# USB0_MMR_MMRVBP_USBSS_CMN register map
Vendor: Texas Instruments
Peripheral module from a debugger description file (folder J7VCL).
Registers are 32-bit, access per field, reset 0x0 unless marked. A register's access mark holds for its fields unless they carry their own. Offsets are as the file gives them; lines under a group give offsets from that group; [hi:lo] are bit positions; {n}, {i} and the like mark numbered series; 'fields as' and 'values as' point back to an identical list; <NAME> marks a mode.

## USB0_MMR_MMRVBP_USBSS_CMN
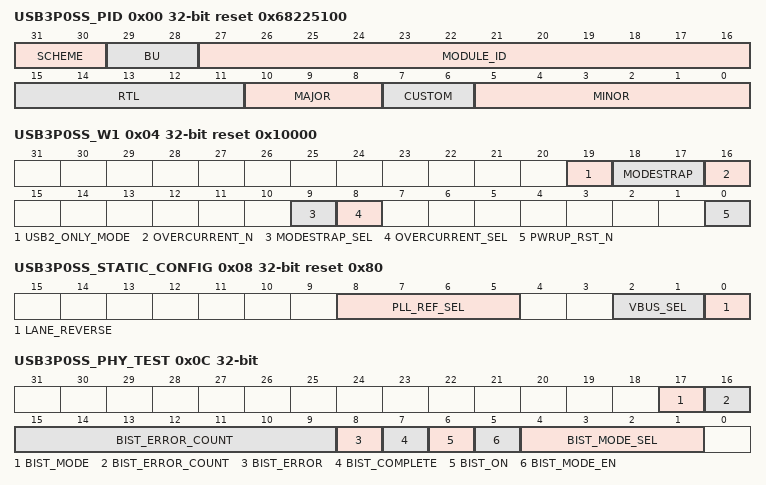
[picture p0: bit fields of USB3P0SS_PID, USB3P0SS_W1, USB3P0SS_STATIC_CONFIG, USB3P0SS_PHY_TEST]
0x00 USB3P0SS_PID ro reset 0x68225100 — The Revision Register contains the major and minor revisions for the module.
  [31:30] SCHEME
  [29:28] BU
  [27:16] MODULE_ID
  [15:11] RTL — RTL revision.
  [10:8] MAJOR — Major revision
  [7:6] CUSTOM
  [5:0] MINOR — Minor revision
0x04 USB3P0SS_W1 reset 0x10000 — Wrapper register containing soft reset, mode selection, and overcurrent indicator.
  [19] USB2_ONLY_MODE rw — Selects USB2 only mode.
  [18:17] MODESTRAP rw — Modestrap input to the Controller.
  [16] OVERCURRENT_N rw — Overcurrent indicator to the controller. Software writes 0 when overcurrent was detected by external circuitry.
  [9] MODESTRAP_SEL rw — This bit has to be always set to 1.
  [8] OVERCURRENT_SEL rw — Overcurrent select.
  [0] PWRUP_RST_N rw — Power up reset for the controller.
0x08 USB3P0SS_STATIC_CONFIG reset 0x80 — Wrapper register containing static settings. All bits in this register have to be written before setting PWRUP_RST_N bit in register.
  [8:5] PLL_REF_SEL rw — Indicates the frequency of the REF_CLOCK input used by the USB PLL.
  [2:1] VBUS_SEL rw — VBUS select. Always set to 0x1
  [0] LANE_REVERSE rw — USB2PHY D+/D- reverse selection.
0x0C USB3P0SS_PHY_TEST — Register containing PLL bypass select, BIST control and status
  [17] BIST_MODE rw — Set for bist mode.
  [16:9] BIST_ERROR_COUNT ro — Number of bytes that have errors while running BIST.
  [8] BIST_ERROR ro — If set, this bit indicates that BIST completed with error.
  [7] BIST_COMPLETE ro — If set, this bit indicates that the BIST operation is completed.
  [6] BIST_ON rw — Setting this bit starts the BIST operation.
  [5] BIST_MODE_EN rw — BIST Mode Enable.
  [4:1] BIST_MODE_SEL rw — BIST Mode Selection.
0x10 USB3P0SS_DEBUG_CTRL — USB Controller debug selection register
  [4:0] DEBUG_SEL rw — Debug selection to be shown in DEBUG_INFO
0x14 USB3P0SS_DEBUG_INFO ro — USB Controller debug information register
  [31:0] DEBUG_INFO — Debug information selected by DEBUG_SEL
0x18 USB3P0SS_DEBUG_LINK_STATE ro — USB Controller debug link state information
  [30:0] DEBUG_LINK_STATE — Debug link state information
0x1C USB3P0SS_DEVICE_CTRL — Register for device control
  [0] DEV_WAKEUP rw — Set this bit to trigger device wakeup interrupt on IRQ[7]
